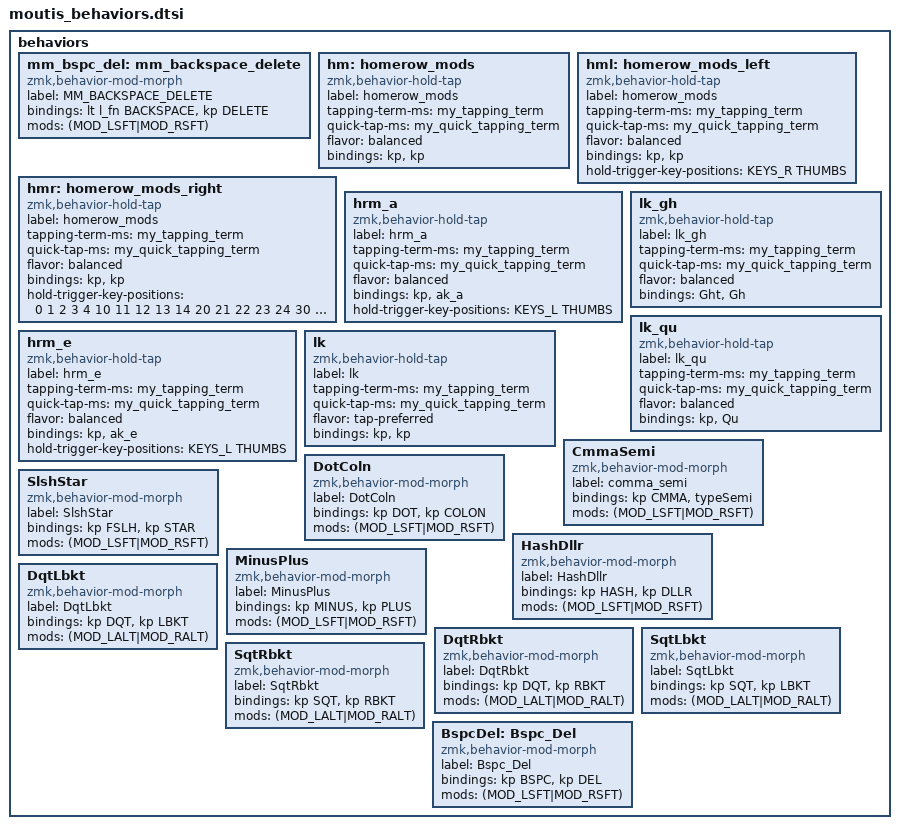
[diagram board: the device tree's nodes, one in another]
/*    KEY POSITIONS for Zaphod
╭────────────────╮ ╭────────────────╮
│  0  1  2  3  4 │ │  5  6  7  8  9 │
│ 10 11 12 13 14 │ │ 15 16 17 18 19 |
| 20 21 22 23 24 │ │ 25 26 27 28 29 |
╰────────╮ 30 31 | | 32 33 ╭────────╯
         ╰───────╯ ╰───────╯   */

behaviors {
        mm_bspc_del: mm_backspace_delete {
            compatible = "zmk,behavior-mod-morph";
            label = "MM_BACKSPACE_DELETE";
            #binding-cells = <0>;
            bindings = <&lt l_fn BACKSPACE>, <&kp DELETE>;
            mods = <(MOD_LSFT|MOD_RSFT)>;
        };
        hm: homerow_mods { // use on either hand
            compatible = "zmk,behavior-hold-tap";
            label = "homerow_mods";
            #binding-cells = <2>;
            tapping-term-ms = <my_tapping_term>;
            quick-tap-ms = <my_quick_tapping_term>;
            flavor = "balanced";
            bindings = <&kp>, <&kp>;
        };
        hmr: homerow_mods_right { // use on right hand to mod left
            compatible = "zmk,behavior-hold-tap";
            label = "homerow_mods";
            #binding-cells = <2>;
            tapping-term-ms = <my_tapping_term>;
            quick-tap-ms = <my_quick_tapping_term>;
            flavor = "balanced";
            bindings = <&kp>, <&kp>;
            hold-trigger-key-positions = <0 1 2 3 4 10 11 12 13 14 20 21 22 23 24 30 31>; // left hand allowed
        };
        hml: homerow_mods_left { // use on left hand to mod right
            compatible = "zmk,behavior-hold-tap";
            label = "homerow_mods";
            #binding-cells = <2>;
            tapping-term-ms = <my_tapping_term>;
            quick-tap-ms = <my_quick_tapping_term>;
            flavor = "balanced";
            bindings = <&kp>, <&kp>;
            hold-trigger-key-positions = <KEYS_R THUMBS>; // right hand allowed
        };
        hrm_a: hrm_a {
            compatible = "zmk,behavior-hold-tap";
            label = "hrm_a";
            #binding-cells = <2>;
            tapping-term-ms = <my_tapping_term>;
            quick-tap-ms = <my_quick_tapping_term>;
            flavor = "balanced";
            bindings = <&kp>, <&ak_a>;
            hold-trigger-key-positions = <KEYS_L THUMBS>; // left hand allowed
        };
        hrm_e: hrm_e {
            compatible = "zmk,behavior-hold-tap";
            label = "hrm_e";
            #binding-cells = <2>;
            tapping-term-ms = <my_tapping_term>;
            quick-tap-ms = <my_quick_tapping_term>;
            flavor = "balanced";
            bindings = <&kp>, <&ak_e>;
            hold-trigger-key-positions = <KEYS_L THUMBS>; // left hand allowed
        };

        lk_gh: lk_gh {
            compatible = "zmk,behavior-hold-tap";
            label = "lk_gh";
            #binding-cells = <2>;
            tapping-term-ms = <my_tapping_term>;
            quick-tap-ms = <my_quick_tapping_term>;
            flavor = "balanced";
            bindings = <&Ght>, <&Gh>;
        };


        lk_qu: lk_qu {
            compatible = "zmk,behavior-hold-tap";
            label = "lk_qu";
            #binding-cells = <2>;
            tapping-term-ms = <my_tapping_term>;
            quick-tap-ms = <my_quick_tapping_term>;
            flavor = "balanced";
            bindings = <&kp>, <&Qu>;
        };
        lk: lk {
            compatible = "zmk,behavior-hold-tap";
            label = "lk";
            #binding-cells = <2>;
            tapping-term-ms = <my_tapping_term>;
            quick-tap-ms = <my_quick_tapping_term>;
            flavor = "tap-preferred";
            bindings = <&kp>, <&kp>;
        };

        CmmaSemi: CmmaSemi {
            compatible = "zmk,behavior-mod-morph";
            label = "comma_semi";
            #binding-cells = <0>;
            bindings = <&kp CMMA>, <&typeSemi>;
            mods = <(MOD_LSFT|MOD_RSFT)>;
        };
        DotColn: DotColn {
            compatible = "zmk,behavior-mod-morph";
            label = "DotColn";
            #binding-cells = <0>;
            bindings = <&kp DOT>, <&kp COLON>;
            mods = <(MOD_LSFT|MOD_RSFT)>;
        };
        SlshStar: SlshStar {
            compatible = "zmk,behavior-mod-morph";
            label = "SlshStar";
            #binding-cells = <0>;
            bindings = <&kp FSLH>, <&kp STAR>;
            mods = <(MOD_LSFT|MOD_RSFT)>;
        };
        HashDllr: HashDllr {
            compatible = "zmk,behavior-mod-morph";
            label = "HashDllr";
            #binding-cells = <0>;
            bindings = <&kp HASH>, <&kp DLLR>;
            mods = <(MOD_LSFT|MOD_RSFT)>;
        };
        MinusPlus: MinusPlus {
            compatible = "zmk,behavior-mod-morph";
            label = "MinusPlus";
            #binding-cells = <0>;
            bindings = <&kp MINUS>, <&kp PLUS>;
            mods = <(MOD_LSFT|MOD_RSFT)>;
        };
        DqtLbkt: DqtLbkt {
            compatible = "zmk,behavior-mod-morph";
            label = "DqtLbkt";
            #binding-cells = <0>;
            bindings = <&kp DQT>, <&kp LBKT>;
            mods = <(MOD_LALT|MOD_RALT)>;
        };
        DqtRbkt: DqtRbkt {
            compatible = "zmk,behavior-mod-morph";
            label = "DqtRbkt";
            #binding-cells = <0>;
            bindings = <&kp DQT>, <&kp RBKT>;
            mods = <(MOD_LALT|MOD_RALT)>;
        };
        SqtLbkt: SqtLbkt {
            compatible = "zmk,behavior-mod-morph";
            label = "SqtLbkt";
            #binding-cells = <0>;
            bindings = <&kp SQT>, <&kp LBKT>;
            mods = <(MOD_LALT|MOD_RALT)>;
        };
        SqtRbkt: SqtRbkt {
            compatible = "zmk,behavior-mod-morph";
            label = "SqtRbkt";
            #binding-cells = <0>;
            bindings = <&kp SQT>, <&kp RBKT>;
            mods = <(MOD_LALT|MOD_RALT)>;
        };
        BspcDel: Bspc_Del {
            compatible = "zmk,behavior-mod-morph";
            label = "Bspc_Del";
            #binding-cells = <0>;
            bindings = <&kp BSPC>, <&kp DEL>;
            mods = <(MOD_LSFT|MOD_RSFT)>;
        };
};
